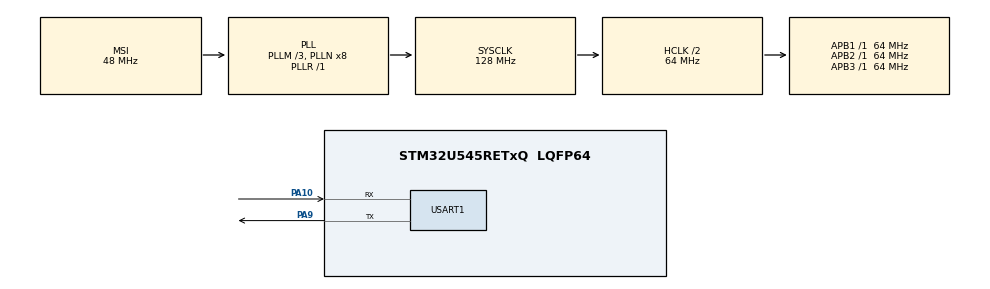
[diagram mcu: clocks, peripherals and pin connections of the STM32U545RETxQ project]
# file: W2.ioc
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CORTEX_M33_NS.userName=CORTEX_M33
Mcu.Family=STM32U5
Mcu.Name=STM32U545RETxQ
Mcu.Package=LQFP64
NVIC.PriorityGroup=NVIC_PRIORITYGROUP_4
PA10.Mode=Asynchronous
PA10.Signal=USART1_RX
PA9.Mode=Asynchronous
PA9.Signal=USART1_TX
PC14-OSC32_IN\ (PC14).Mode=LSE-External-Oscillator
PC14-OSC32_IN\ (PC14).Signal=RCC_OSC32_IN
PC15-OSC32_OUT\ (PC15).Mode=LSE-External-Oscillator
PC15-OSC32_OUT\ (PC15).Signal=RCC_OSC32_OUT
PWR.PowerMode=PWR_SMPS_SUPPLY
ProjectManager.HeapSize=0x200
ProjectManager.StackSize=0x400
ProjectManager.TargetToolchain=STM32CubeIDE
RCC.ADCFreq_Value=16000000
RCC.AHBCLKDivider=RCC_SYSCLK_DIV2
RCC.AHBFreq_Value=64000000
RCC.APB1Freq_Value=64000000
RCC.APB1TimFreq_Value=64000000
RCC.APB2Freq_Value=64000000
RCC.APB2TimFreq_Value=64000000
RCC.APB3Freq_Value=64000000
RCC.CortexFreq_Value=64000000
RCC.DACCLockSelectionVirtual=RCC_DAC1CLKSOURCE_LSI
RCC.DACCLockSelectionVirtualString=RCC_DAC1CLKSOURCE_LSI
RCC.EPOD_VALUE=48000000
RCC.HCLKFreq_Value=64000000
RCC.HSE_VALUE=16000000
RCC.HSI48_VALUE=48000000
RCC.HSI_VALUE=16000000
RCC.LSIDIV_VALUE=32000
RCC.MSIClockRange=RCC_MSIRANGE_0
RCC.MSI_VALUE=48000000
RCC.PLL1R=1
RCC.PLL2FRACN=0
RCC.PLL3FRACN=0
RCC.PLLFRACN=0
RCC.PLLM=3
RCC.PLLN=8
RCC.RTCClockSelection=RCC_RTCCLKSOURCE_LSE
RCC.SYSCLKFreq_VALUE=128000000
RCC.SYSCLKSource=RCC_SYSCLKSOURCE_PLLCLK
RCC.USBFreq_Value=48000000
RCC.VCOOutputFreq_Value=128000000
RTC.Date=3
RTC.Format=RTC_FORMAT_BIN
RTC.Hours=17
RTC.Minutes=45
RTC.Month=RTC_MONTH_MARCH
RTC.WeekDay=RTC_WEEKDAY_TUESDAY
USART1.VirtualMode-Asynchronous=VM_ASYNC
VP_LPBAMQUEUE_VS_QUEUE.Mode=QUEUEMODE
VP_MEMORYMAP_VS_MEMORYMAP.Mode=CurAppReg
VP_PWR_VS_LPOM.Mode=PowerOptimisation
VP_PWR_VS_SECSignals.Mode=Security/Privilege
VP_RTC_VS_RTC_Activate.Mode=RTC_Enabled
VP_RTC_VS_RTC_Calendar.Mode=RTC_Calendar
board=custom

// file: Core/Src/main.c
/* USER CODE BEGIN Header */
/**
  ******************************************************************************
  * @file           : main.c
  * @brief          : Main program body
  ******************************************************************************
  * @attention
  *
  * Copyright (c) 2025 STMicroelectronics.
  * All rights reserved.
  *
  * This software is licensed under terms that can be found in the LICENSE file
  * in the root directory of this software component.
  * If no LICENSE file comes with this software, it is provided AS-IS.
  *
  ******************************************************************************
  */
/* USER CODE END Header */
#include "main.h"

RTC_HandleTypeDef hrtc;

UART_HandleTypeDef huart1;

void SystemClock_Config(void);
static void SystemPower_Config(void);
static void MX_GPIO_Init(void);
static void MX_USART1_UART_Init(void);
static void MX_RTC_Init(void);

/* USER CODE BEGIN 0 */

int __io_putchar(int ch){
	HAL_UART_Transmit(&huart1, (uint8_t*)&ch, 1, HAL_MAX_DELAY);
	return 1;
}

/* USER CODE END 0 */

int main(void)
{

  /* MCU Configuration--------------------------------------------------------*/

  /* Reset of all peripherals, Initializes the Flash interface and the Systick. */
  HAL_Init();

  /* Configure the System Power */
  SystemPower_Config();

  /* Configure the system clock */
  SystemClock_Config();

  /* Initialize all configured peripherals */
  MX_GPIO_Init();
  MX_USART1_UART_Init();
  MX_RTC_Init();
  /* USER CODE BEGIN 2 */
  RTC_TimeTypeDef myTime;
  myTime.Hours = (uint8_t) 18;
  myTime.Minutes = (uint8_t) 50;
  myTime.Seconds = (uint8_t) 0;
  RTC_DateTypeDef myDate;
  myDate.WeekDay = RTC_WEEKDAY_TUESDAY;
  myDate.Month = RTC_MONTH_MARCH;
  myDate.Date = 3;
  myDate.Year = 25;
  HAL_RTC_SetTime(&hrtc, &myTime, RTC_FORMAT_BIN);
  HAL_RTC_SetDate(&hrtc, &myDate, RTC_FORMAT_BIN);

  /* USER CODE END 2 */

  /* Infinite loop */
  /* USER CODE BEGIN WHILE */
  while (1)
  {
	  //char buffer[50];

	  HAL_RTC_GetTime(&hrtc, &myTime, RTC_FORMAT_BIN);
	  HAL_RTC_GetDate(&hrtc, &myDate, RTC_FORMAT_BIN);
	  printf("Hello there\n\r");
	  printf("Clock: %02d:%02d:%02d\n\r", myTime.Hours, myTime.Minutes, myTime.Seconds);
	  printf("Today is: %02d.%02d.20%02d\n\r", myDate.Date, myDate.Month, myDate.Year);
	  //sprintf(buffer, "-> Time Value: %02d:%02d:%02d\n\r", myTime.Hours, myTime.Minutes, myTime.Seconds);
	  //HAL_UART_Transmit(&huart1, (uint8_t*)buffer, strlen(buffer), HAL_MAX_DELAY);
	  HAL_Delay(1000);
    /* USER CODE END WHILE */

  }
}

void SystemClock_Config(void)
{
  RCC_OscInitTypeDef RCC_OscInitStruct = {0};
  RCC_ClkInitTypeDef RCC_ClkInitStruct = {0};

  /** Configure the main internal regulator output voltage
  */
  if (HAL_PWREx_ControlVoltageScaling(PWR_REGULATOR_VOLTAGE_SCALE1) != HAL_OK)
  {
    Error_Handler();
  }

  /** Configure LSE Drive Capability
  */
  HAL_PWR_EnableBkUpAccess();
  __HAL_RCC_LSEDRIVE_CONFIG(RCC_LSEDRIVE_LOW);

  /** Initializes the CPU, AHB and APB buses clocks
  */
  RCC_OscInitStruct.OscillatorType = RCC_OSCILLATORTYPE_LSE|RCC_OSCILLATORTYPE_MSI;
  RCC_OscInitStruct.LSEState = RCC_LSE_ON;
  RCC_OscInitStruct.MSIState = RCC_MSI_ON;
  RCC_OscInitStruct.MSICalibrationValue = RCC_MSICALIBRATION_DEFAULT;
  RCC_OscInitStruct.MSIClockRange = RCC_MSIRANGE_0;
  RCC_OscInitStruct.PLL.PLLState = RCC_PLL_ON;
  RCC_OscInitStruct.PLL.PLLSource = RCC_PLLSOURCE_MSI;
  RCC_OscInitStruct.PLL.PLLMBOOST = RCC_PLLMBOOST_DIV4;
  RCC_OscInitStruct.PLL.PLLM = 3;
  RCC_OscInitStruct.PLL.PLLN = 8;
  RCC_OscInitStruct.PLL.PLLP = 2;
  RCC_OscInitStruct.PLL.PLLQ = 2;
  RCC_OscInitStruct.PLL.PLLR = 1;
  RCC_OscInitStruct.PLL.PLLRGE = RCC_PLLVCIRANGE_1;
  RCC_OscInitStruct.PLL.PLLFRACN = 0;
  if (HAL_RCC_OscConfig(&RCC_OscInitStruct) != HAL_OK)
  {
    Error_Handler();
  }

  /** Initializes the CPU, AHB and APB buses clocks
  */
  RCC_ClkInitStruct.ClockType = RCC_CLOCKTYPE_HCLK|RCC_CLOCKTYPE_SYSCLK
                              |RCC_CLOCKTYPE_PCLK1|RCC_CLOCKTYPE_PCLK2
                              |RCC_CLOCKTYPE_PCLK3;
  RCC_ClkInitStruct.SYSCLKSource = RCC_SYSCLKSOURCE_PLLCLK;
  RCC_ClkInitStruct.AHBCLKDivider = RCC_SYSCLK_DIV2;
  RCC_ClkInitStruct.APB1CLKDivider = RCC_HCLK_DIV1;
  RCC_ClkInitStruct.APB2CLKDivider = RCC_HCLK_DIV1;
  RCC_ClkInitStruct.APB3CLKDivider = RCC_HCLK_DIV1;

  if (HAL_RCC_ClockConfig(&RCC_ClkInitStruct, FLASH_LATENCY_1) != HAL_OK)
  {
    Error_Handler();
  }
}

/**
  * @brief Power Configuration
  * @retval None
  */
static void SystemPower_Config(void)
{

  /*
   * Switch to SMPS regulator instead of LDO
   */
  if (HAL_PWREx_ConfigSupply(PWR_SMPS_SUPPLY) != HAL_OK)
  {
    Error_Handler();
  }
}

static void MX_RTC_Init(void)
{

  RTC_PrivilegeStateTypeDef privilegeState = {0};
  RTC_TimeTypeDef sTime = {0};
  RTC_DateTypeDef sDate = {0};

  /** Initialize RTC Only
  */
  hrtc.Instance = RTC;
  hrtc.Init.HourFormat = RTC_HOURFORMAT_24;
  hrtc.Init.AsynchPrediv = 127;
  hrtc.Init.SynchPrediv = 255;
  hrtc.Init.OutPut = RTC_OUTPUT_DISABLE;
  hrtc.Init.OutPutRemap = RTC_OUTPUT_REMAP_NONE;
  hrtc.Init.OutPutPolarity = RTC_OUTPUT_POLARITY_HIGH;
  hrtc.Init.OutPutType = RTC_OUTPUT_TYPE_OPENDRAIN;
  hrtc.Init.OutPutPullUp = RTC_OUTPUT_PULLUP_NONE;
  hrtc.Init.BinMode = RTC_BINARY_NONE;
  if (HAL_RTC_Init(&hrtc) != HAL_OK)
  {
    Error_Handler();
  }
  privilegeState.rtcPrivilegeFull = RTC_PRIVILEGE_FULL_NO;
  privilegeState.backupRegisterPrivZone = RTC_PRIVILEGE_BKUP_ZONE_NONE;
  privilegeState.backupRegisterStartZone2 = RTC_BKP_DR0;
  privilegeState.backupRegisterStartZone3 = RTC_BKP_DR0;
  if (HAL_RTCEx_PrivilegeModeSet(&hrtc, &privilegeState) != HAL_OK)
  {
    Error_Handler();
  }

  /** Initialize RTC and set the Time and Date
  */
  sTime.Hours = 17;
  sTime.Minutes = 45;
  sTime.Seconds = 0;
  sTime.DayLightSaving = RTC_DAYLIGHTSAVING_NONE;
  sTime.StoreOperation = RTC_STOREOPERATION_RESET;
  if (HAL_RTC_SetTime(&hrtc, &sTime, RTC_FORMAT_BIN) != HAL_OK)
  {
    Error_Handler();
  }
  sDate.WeekDay = RTC_WEEKDAY_TUESDAY;
  sDate.Month = RTC_MONTH_MARCH;
  sDate.Date = 3;
  sDate.Year = 0;

  if (HAL_RTC_SetDate(&hrtc, &sDate, RTC_FORMAT_BIN) != HAL_OK)
  {
    Error_Handler();
  }

}

static void MX_USART1_UART_Init(void)
{

  huart1.Instance = USART1;
  huart1.Init.BaudRate = 115200;
  huart1.Init.WordLength = UART_WORDLENGTH_8B;
  huart1.Init.StopBits = UART_STOPBITS_1;
  huart1.Init.Parity = UART_PARITY_NONE;
  huart1.Init.Mode = UART_MODE_TX_RX;
  huart1.Init.HwFlowCtl = UART_HWCONTROL_NONE;
  huart1.Init.OverSampling = UART_OVERSAMPLING_16;
  huart1.Init.OneBitSampling = UART_ONE_BIT_SAMPLE_DISABLE;
  huart1.Init.ClockPrescaler = UART_PRESCALER_DIV1;
  huart1.AdvancedInit.AdvFeatureInit = UART_ADVFEATURE_NO_INIT;
  if (HAL_UART_Init(&huart1) != HAL_OK)
  {
    Error_Handler();
  }
  if (HAL_UARTEx_SetTxFifoThreshold(&huart1, UART_TXFIFO_THRESHOLD_1_8) != HAL_OK)
  {
    Error_Handler();
  }
  if (HAL_UARTEx_SetRxFifoThreshold(&huart1, UART_RXFIFO_THRESHOLD_1_8) != HAL_OK)
  {
    Error_Handler();
  }
  if (HAL_UARTEx_DisableFifoMode(&huart1) != HAL_OK)
  {
    Error_Handler();
  }

}

static void MX_GPIO_Init(void)
{

  /* GPIO Ports Clock Enable */
  __HAL_RCC_GPIOC_CLK_ENABLE();
  __HAL_RCC_GPIOA_CLK_ENABLE();

}

void Error_Handler(void)
{
  __disable_irq();
  while (1)
  {
  }
}
